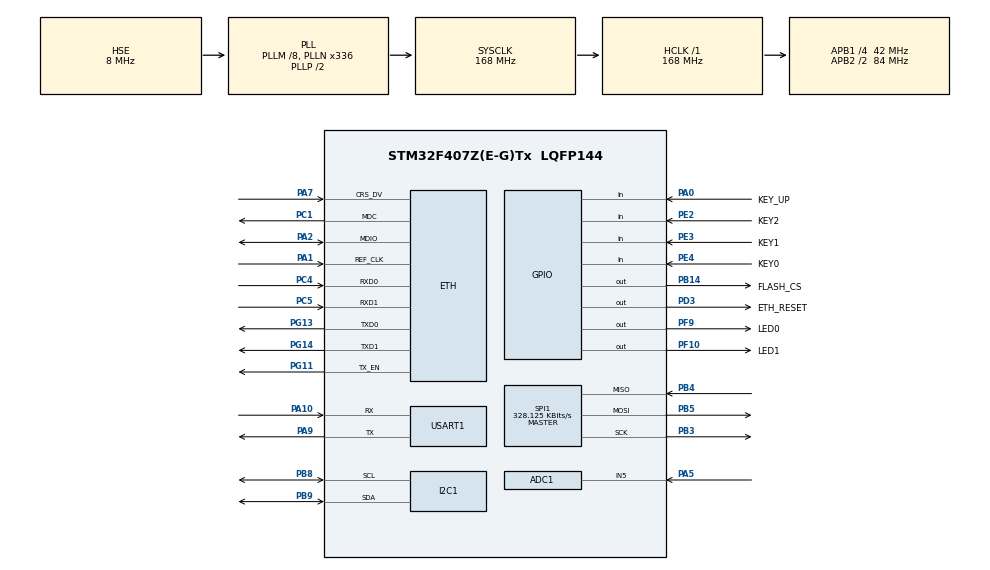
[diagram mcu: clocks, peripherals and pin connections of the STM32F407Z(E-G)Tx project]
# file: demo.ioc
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ADC1.Channel-0\#ChannelRegularConversion=ADC_CHANNEL_5
ADC1.Channel-1\#ChannelInjectedConversion=ADC_CHANNEL_5
ADC1.InjNumberOfConversion=1
ADC1.InjectedOffset-1\#ChannelInjectedConversion=0
ADC1.InjectedRank-1\#ChannelInjectedConversion=1
ADC1.NbrOfConversionFlag=1
ADC1.Rank-0\#ChannelRegularConversion=1
ADC1.SamplingTime-0\#ChannelRegularConversion=ADC_SAMPLETIME_480CYCLES
ADC1.SamplingTime-1\#ChannelInjectedConversion=ADC_SAMPLETIME_3CYCLES
ADC1.master=1
Dma.Request0=USART1_TX
Dma.Request1=USART1_RX
Dma.USART1_RX.1.Direction=DMA_PERIPH_TO_MEMORY
Dma.USART1_RX.1.FIFOMode=DMA_FIFOMODE_DISABLE
Dma.USART1_RX.1.Instance=DMA2_Stream5
Dma.USART1_RX.1.MemDataAlignment=DMA_MDATAALIGN_BYTE
Dma.USART1_RX.1.MemInc=DMA_MINC_ENABLE
Dma.USART1_RX.1.Mode=DMA_CIRCULAR
Dma.USART1_RX.1.PeriphDataAlignment=DMA_PDATAALIGN_BYTE
Dma.USART1_RX.1.PeriphInc=DMA_PINC_DISABLE
Dma.USART1_RX.1.Priority=DMA_PRIORITY_LOW
Dma.USART1_TX.0.Direction=DMA_MEMORY_TO_PERIPH
Dma.USART1_TX.0.FIFOMode=DMA_FIFOMODE_DISABLE
Dma.USART1_TX.0.Instance=DMA2_Stream7
Dma.USART1_TX.0.MemDataAlignment=DMA_MDATAALIGN_BYTE
Dma.USART1_TX.0.MemInc=DMA_MINC_ENABLE
Dma.USART1_TX.0.Mode=DMA_NORMAL
Dma.USART1_TX.0.PeriphDataAlignment=DMA_PDATAALIGN_BYTE
Dma.USART1_TX.0.PeriphInc=DMA_PINC_DISABLE
Dma.USART1_TX.0.Priority=DMA_PRIORITY_LOW
ETH.MediaInterface=HAL_ETH_RMII_MODE
FREERTOS.Tasks01=defaultTask,24,128,StartDefaultTask,Default,NULL,Dynamic,NULL,NULL
LWIP.BSP.number=1
LWIP.GATEWAY_ADDRESS=192.168.010.001
LWIP.IP_ADDRESS=192.168.010.002
LWIP.LWIP_DHCP=0
LWIP.LWIP_DNS=1
LWIP.LWIP_RAW=0
LWIP.MEMP_NUM_SYS_TIMEOUT=10
LWIP.NETMASK_ADDRESS=255.255.255.000
LWIP.Version=v2.1.2_Cube
LWIP0.BSP.STBoard=false
LWIP0.BSP.api=BSP_COMPONENT_DRIVER
LWIP0.BSP.component=LAN8742
LWIP0.BSP.instance=LAN8742
LWIP0.BSP.name=Driver_PHY
LWIP0.BSP.semaphore=S_LAN8742
LWIP0.BSP.solution=LAN8742
Mcu.Family=STM32F4
Mcu.Name=STM32F407Z(E-G)Tx
Mcu.Package=LQFP144
NVIC.DMA2_Stream5_IRQn=true\:5\:0\:false\:false\:true\:true\:false\:true\:true
NVIC.DMA2_Stream7_IRQn=true\:5\:0\:false\:false\:true\:true\:false\:true\:true
NVIC.ETH_IRQn=true\:5\:0\:false\:false\:true\:true\:false\:true\:true
NVIC.PriorityGroup=NVIC_PRIORITYGROUP_4
NVIC.TIM6_DAC_IRQn=true\:15\:0\:false\:false\:true\:false\:false\:true\:true
NVIC.TimeBase=TIM6_DAC_IRQn
NVIC.TimeBaseIP=TIM6
PA0-WKUP.GPIO_Label=KEY_UP
PA0-WKUP.GPIO_PuPd=GPIO_PULLDOWN
PA0-WKUP.Signal=GPIO_Input
PA1.Mode=RMII
PA1.Signal=ETH_REF_CLK
PA10.Mode=Asynchronous
PA10.Signal=USART1_RX
PA13.Mode=Serial_Wire
PA13.Signal=SYS_JTMS-SWDIO
PA14.Mode=Serial_Wire
PA14.Signal=SYS_JTCK-SWCLK
PA2.Mode=RMII
PA2.Signal=ETH_MDIO
PA5.Signal=ADCx_IN5
PA7.Mode=RMII
PA7.Signal=ETH_CRS_DV
PA9.Mode=Asynchronous
PA9.Signal=USART1_TX
PB14.GPIO_Label=FLASH_CS
PB14.GPIO_PuPd=GPIO_NOPULL
PB14.PinState=GPIO_PIN_SET
PB14.Signal=GPIO_Output
PB3.Mode=Full_Duplex_Master
PB3.Signal=SPI1_SCK
PB4.Mode=Full_Duplex_Master
PB4.Signal=SPI1_MISO
PB5.Mode=Full_Duplex_Master
PB5.Signal=SPI1_MOSI
PB8.Mode=I2C
PB8.Signal=I2C1_SCL
PB9.Mode=I2C
PB9.Signal=I2C1_SDA
PC1.Mode=RMII
PC1.Signal=ETH_MDC
PC4.Mode=RMII
PC4.Signal=ETH_RXD0
PC5.Mode=RMII
PC5.Signal=ETH_RXD1
PD3.GPIO_Label=ETH_RESET
PD3.GPIO_PuPd=GPIO_NOPULL
PD3.PinState=GPIO_PIN_SET
PD3.Signal=GPIO_Output
PE2.GPIO_Label=KEY2
PE2.GPIO_PuPd=GPIO_PULLUP
PE2.Signal=GPIO_Input
PE3.GPIO_Label=KEY1
PE3.GPIO_PuPd=GPIO_PULLUP
PE3.Signal=GPIO_Input
PE4.GPIO_Label=KEY0
PE4.GPIO_PuPd=GPIO_PULLUP
PE4.Signal=GPIO_Input
PF10.GPIO_Label=LED1
PF10.PinState=GPIO_PIN_SET
PF10.Signal=GPIO_Output
PF9.GPIO_Label=LED0
PF9.PinState=GPIO_PIN_SET
PF9.Signal=GPIO_Output
PG11.Mode=RMII
PG11.Signal=ETH_TX_EN
PG13.Mode=RMII
PG13.Signal=ETH_TXD0
PG14.Mode=RMII
PG14.Signal=ETH_TXD1
PH0-OSC_IN.Mode=HSE-External-Oscillator
PH0-OSC_IN.Signal=RCC_OSC_IN
PH1-OSC_OUT.Mode=HSE-External-Oscillator
PH1-OSC_OUT.Signal=RCC_OSC_OUT
ProjectManager.HeapSize=0x200
ProjectManager.StackSize=0x400
ProjectManager.TargetToolchain=CMake
RCC.48MHZClocksFreq_Value=84000000
RCC.AHBFreq_Value=168000000
RCC.APB1CLKDivider=RCC_HCLK_DIV4
RCC.APB1Freq_Value=42000000
RCC.APB1TimFreq_Value=84000000
RCC.APB2CLKDivider=RCC_HCLK_DIV2
RCC.APB2Freq_Value=84000000
RCC.APB2TimFreq_Value=168000000
RCC.CortexFreq_Value=168000000
RCC.EnbaleCSS=true
RCC.HCLKFreq_Value=168000000
RCC.HSE_VALUE=8000000
RCC.HSI_VALUE=16000000
RCC.LSE_VALUE=32768
RCC.PLLM=8
RCC.PLLN=336
RCC.PLLSourceVirtual=RCC_PLLSOURCE_HSE
RCC.SYSCLKFreq_VALUE=168000000
RCC.SYSCLKSource=RCC_SYSCLKSOURCE_PLLCLK
RCC.VCOOutputFreq_Value=336000000
SH.ADCx_IN5.0=ADC1_IN5,IN5
SPI1.BaudRatePrescaler=SPI_BAUDRATEPRESCALER_256
SPI1.CLKPhase=SPI_PHASE_2EDGE
SPI1.CLKPolarity=SPI_POLARITY_HIGH
SPI1.CalculateBaudRate=328.125 KBits/s
SPI1.Direction=SPI_DIRECTION_2LINES
SPI1.Mode=SPI_MODE_MASTER
SPI1.VirtualType=VM_MASTER
USART1.VirtualMode=VM_ASYNC
VP_FREERTOS_VS_CMSIS_V2.Mode=CMSIS_V2
VP_LWIP_VS_Enabled.Mode=Enabled
VP_SYS_VS_tim6.Mode=TIM6
board=custom

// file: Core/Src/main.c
/* USER CODE BEGIN Header */
/**
 ******************************************************************************
 * @file           : main.c
 * @brief          : Main program body
 ******************************************************************************
 * @attention
 *
 * Copyright (c) 2026 STMicroelectronics.
 * All rights reserved.
 *
 * This software is licensed under terms that can be found in the LICENSE file
 * in the root directory of this software component.
 * If no LICENSE file comes with this software, it is provided AS-IS.
 *
 ******************************************************************************
 */
/* USER CODE END Header */
#include "main.h"
#include "cmsis_os.h"
#include "adc.h"
#include "dma.h"
#include "i2c.h"
#include "lwip.h"
#include "spi.h"
#include "usart.h"
#include "gpio.h"

void SystemClock_Config(void);
void MX_FREERTOS_Init(void);

int main(void)
{

  /* MCU Configuration--------------------------------------------------------*/

  /* Reset of all peripherals, Initializes the Flash interface and the Systick. */
  HAL_Init();

  /* Configure the system clock */
  SystemClock_Config();

  /* Initialize all configured peripherals */
  MX_GPIO_Init();
  MX_DMA_Init();
  MX_USART1_UART_Init();
  MX_I2C1_Init();
  MX_SPI1_Init();
  MX_ADC1_Init();

  /* Init scheduler */
  osKernelInitialize();  /* Call init function for freertos objects (in cmsis_os2.c) */
  MX_FREERTOS_Init();

  /* Start scheduler */
  osKernelStart();

  /* We should never get here as control is now taken by the scheduler */

  /* Infinite loop */
  while (1)
  {

  }
}

void SystemClock_Config(void)
{
  RCC_OscInitTypeDef RCC_OscInitStruct = {0};
  RCC_ClkInitTypeDef RCC_ClkInitStruct = {0};

  /** Configure the main internal regulator output voltage
  */
  __HAL_RCC_PWR_CLK_ENABLE();
  __HAL_PWR_VOLTAGESCALING_CONFIG(PWR_REGULATOR_VOLTAGE_SCALE1);

  /** Initializes the RCC Oscillators according to the specified parameters
  * in the RCC_OscInitTypeDef structure.
  */
  RCC_OscInitStruct.OscillatorType = RCC_OSCILLATORTYPE_HSE;
  RCC_OscInitStruct.HSEState = RCC_HSE_ON;
  RCC_OscInitStruct.PLL.PLLState = RCC_PLL_ON;
  RCC_OscInitStruct.PLL.PLLSource = RCC_PLLSOURCE_HSE;
  RCC_OscInitStruct.PLL.PLLM = 8;
  RCC_OscInitStruct.PLL.PLLN = 336;
  RCC_OscInitStruct.PLL.PLLP = RCC_PLLP_DIV2;
  RCC_OscInitStruct.PLL.PLLQ = 4;
  if (HAL_RCC_OscConfig(&RCC_OscInitStruct) != HAL_OK)
  {
    Error_Handler();
  }

  /** Initializes the CPU, AHB and APB buses clocks
  */
  RCC_ClkInitStruct.ClockType = RCC_CLOCKTYPE_HCLK|RCC_CLOCKTYPE_SYSCLK
                              |RCC_CLOCKTYPE_PCLK1|RCC_CLOCKTYPE_PCLK2;
  RCC_ClkInitStruct.SYSCLKSource = RCC_SYSCLKSOURCE_PLLCLK;
  RCC_ClkInitStruct.AHBCLKDivider = RCC_SYSCLK_DIV1;
  RCC_ClkInitStruct.APB1CLKDivider = RCC_HCLK_DIV4;
  RCC_ClkInitStruct.APB2CLKDivider = RCC_HCLK_DIV2;

  if (HAL_RCC_ClockConfig(&RCC_ClkInitStruct, FLASH_LATENCY_5) != HAL_OK)
  {
    Error_Handler();
  }

  /** Enables the Clock Security System
  */
  HAL_RCC_EnableCSS();
}

void HAL_TIM_PeriodElapsedCallback(TIM_HandleTypeDef *htim)
{
  if (htim->Instance == TIM6)
  {
    HAL_IncTick();
  }
}

void Error_Handler(void)
{
  /* USER CODE BEGIN Error_Handler_Debug */
  /* User can add his own implementation to report the HAL error return state
   */
  __disable_irq();
  while (1)
  {
  }
  /* USER CODE END Error_Handler_Debug */
}
#ifdef USE_FULL_ASSERT
/**
  * @brief  Reports the name of the source file and the source line number
  *         where the assert_param error has occurred.
  * @param  file: pointer to the source file name
  * @param  line: assert_param error line source number
  * @retval None
  */
void assert_failed(uint8_t *file, uint32_t line)
{
  /* USER CODE BEGIN 6 */
  /* User can add his own implementation to report the file name and line
     number, ex: printf("Wrong parameters value: file %s on line %d\r\n",
     file, line) */
  /* USER CODE END 6 */
}
#endif /* USE_FULL_ASSERT */

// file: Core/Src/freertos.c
/* USER CODE BEGIN Header */
/**
 ******************************************************************************
 * File Name          : freertos.c
 * Description        : Code for freertos applications
 ******************************************************************************
 * @attention
 *
 * Copyright (c) 2026 STMicroelectronics.
 * All rights reserved.
 *
 * This software is licensed under terms that can be found in the LICENSE file
 * in the root directory of this software component.
 * If no LICENSE file comes with this software, it is provided AS-IS.
 *
 ******************************************************************************
 */
/* USER CODE END Header */

#include "FreeRTOS.h"
#include "task.h"
#include "main.h"
#include "cmsis_os.h"

/* USER CODE BEGIN Includes */
#include "task.h"

/* USER CODE END Includes */

/* USER CODE BEGIN Variables */
osThreadId_t networkStatusTaskHandle;
const osThreadAttr_t networkStatusTask_attributes = {
    .name = "NetworkStatus",
    .stack_size = 1024,
    .priority = osPriorityNormal,
};

/* USER CODE END Variables */
/* Definitions for defaultTask */
osThreadId_t defaultTaskHandle;
const osThreadAttr_t defaultTask_attributes = {
  .name = "defaultTask",
  .stack_size = 128 * 4,
  .priority = (osPriority_t) osPriorityNormal,
};

/* USER CODE BEGIN FunctionPrototypes */
void NetworkStatusTask(void *argument);

/* USER CODE END FunctionPrototypes */

void StartDefaultTask(void *argument);

extern void MX_LWIP_Init(void);
void MX_FREERTOS_Init(void); /* (MISRA C 2004 rule 8.1) */

void MX_FREERTOS_Init(void) {

  /* Create the thread(s) */
  /* creation of defaultTask */
  defaultTaskHandle = osThreadNew(StartDefaultTask, NULL, &defaultTask_attributes);

  /* USER CODE BEGIN RTOS_THREADS */
  networkStatusTaskHandle =
      osThreadNew(NetworkStatusTask, NULL, &networkStatusTask_attributes);

  /* add threads, ... */
  /* USER CODE END RTOS_THREADS */

}

void StartDefaultTask(void *argument)
{
  /* init code for LWIP */
  MX_LWIP_Init();
  for (;;)
  {
    osDelay(1);
  }
}
